VERSION ""

NS_ :

BS_:

BU_: XXX

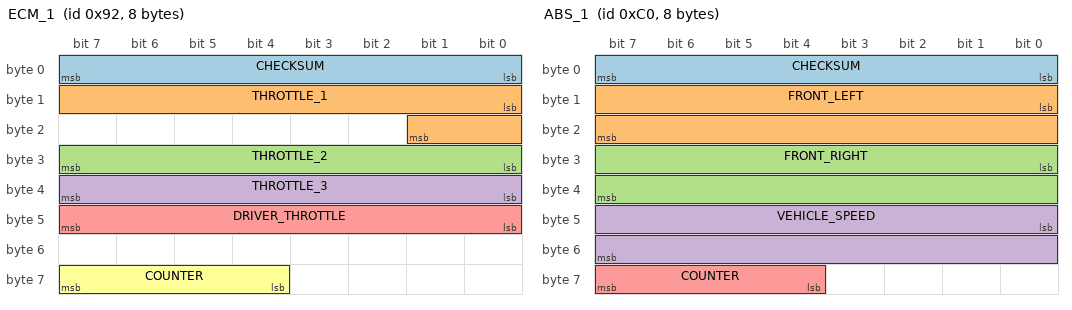
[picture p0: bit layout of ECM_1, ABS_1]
BO_ 146 ECM_1: 8 XXX
 SG_ CHECKSUM : 0|8@1+ (1,0) [0|255] "" XXX
 SG_ THROTTLE_1 : 8|10@1+ (1,0) [0|255] "x" XXX
 SG_ THROTTLE_2 : 24|8@1+ (1,0) [0|255] "" XXX
 SG_ THROTTLE_3 : 32|8@1+ (1,0) [0|255] "" XXX
 SG_ DRIVER_THROTTLE : 40|8@1+ (1,0) [0|255] "" XXX
 SG_ COUNTER : 60|4@1+ (1,0) [0|15] "" XXX

BO_ 192 ABS_1: 8 XXX
 SG_ CHECKSUM : 0|8@1+ (1,0) [0|15] "" XXX
 SG_ FRONT_LEFT : 8|16@1+ (0.01,0) [0|65535] "km/h" XXX
 SG_ FRONT_RIGHT : 24|16@1+ (0.01,0) [0|65535] "km/h" XXX
 SG_ VEHICLE_SPEED : 40|16@1+ (0.01,0) [0|65535] "km/h" XXX
 SG_ COUNTER : 60|4@1+ (1,0) [0|15] "" XXX

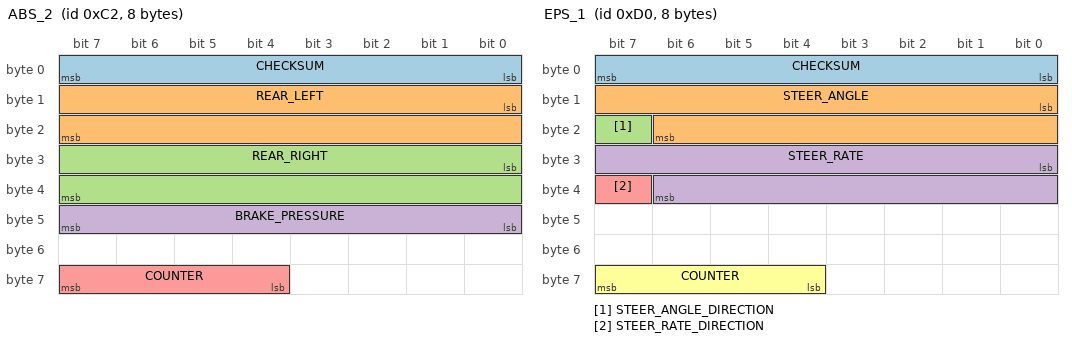
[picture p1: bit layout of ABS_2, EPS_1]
BO_ 194 ABS_2: 8 XXX
 SG_ CHECKSUM : 0|8@1+ (1,0) [0|15] "" XXX
 SG_ REAR_LEFT : 8|16@1+ (0.01,0) [0|65535] "km/h" XXX
 SG_ REAR_RIGHT : 24|16@1+ (0.01,0) [0|65535] "km/h" XXX
 SG_ BRAKE_PRESSURE : 40|8@1+ (1,0) [0|255] "" XXX
 SG_ COUNTER : 60|4@1+ (1,0) [0|15] "" XXX

BO_ 208 EPS_1: 8 XXX
 SG_ CHECKSUM : 0|8@1+ (1,0) [0|15] "" XXX
 SG_ STEER_ANGLE : 8|15@1+ (0.0225,0) [0|65535] "" XXX
 SG_ STEER_ANGLE_DIRECTION : 23|1@1+ (1,0) [0|1] "direction" XXX
 SG_ STEER_RATE : 24|15@1+ (0.0225,0) [0|65535] "" XXX
 SG_ STEER_RATE_DIRECTION : 39|1@1+ (1,0) [0|1] "direction" XXX
 SG_ COUNTER : 60|4@1+ (1,0) [0|15] "" XXX

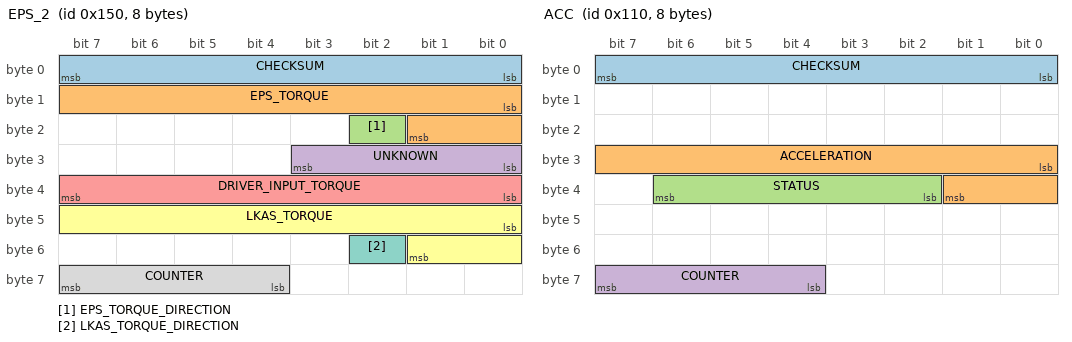
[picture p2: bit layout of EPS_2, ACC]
BO_ 336 EPS_2: 8 XXX
 SG_ CHECKSUM : 0|8@1+ (1,0) [0|255] "" XXX
 SG_ EPS_TORQUE : 8|10@1- (1,0) [0|255] "" XXX
 SG_ EPS_TORQUE_DIRECTION : 18|1@1+ (1,0) [0|1] "direction" XXX
 SG_ UNKNOWN : 24|4@1+ (1,0) [0|15] "" XXX
 SG_ DRIVER_INPUT_TORQUE : 32|8@1+ (1,0) [0|255] "" XXX
 SG_ LKAS_TORQUE : 40|10@1+ (1,0) [0|1023] "" XXX
 SG_ LKAS_TORQUE_DIRECTION : 50|1@1+ (1,0) [0|1] "X" XXX
 SG_ COUNTER : 60|4@1+ (1,0) [0|15] "" XXX

BO_ 272 ACC: 8 XXX
 SG_ CHECKSUM : 0|8@1+ (1,0) [0|255] "" XXX
 SG_ ACCELERATION : 24|10@1+ (1,-300) [0|255] "" XXX
 SG_ STATUS : 34|5@1+ (1,0) [0|31] "" XXX
 SG_ COUNTER : 60|4@1+ (1,0) [0|15] "" XXX

BO_ 274 LKAS: 8 XXX
 SG_ CHECKSUM : 0|8@1+ (1,0) [0|255] "" XXX
 SG_ LKAS_TORQUE : 8|10@1+ (1,0) [0|2047] "x" XXX
 SG_ LKAS_TORQUE_DIRECTION : 18|1@1+ (1,0) [0|1] "" XXX
 SG_ LKAS_TORQUE_ACTIVE : 19|1@1+ (1,0) [0|1] "x" XXX
 SG_ MAYBE_LANE_STATUS : 31|4@1+ (1,0) [0|15] "" XXX
 SG_ LKAS_ACTIVE : 32|1@1+ (1,0) [0|255] "" XXX
 SG_ COUNTER : 60|4@1+ (1,0) [0|15] "" XXX

CM_ SG_ 208 STEER_ANGLE_DIRECTION "0=right, 1=left";
CM_ SG_ 208 STEER_RATE_DIRECTION "0=right, 1=left";
CM_ SG_ 336 EPS_TORQUE_DIRECTION "0=right, 1=left";
